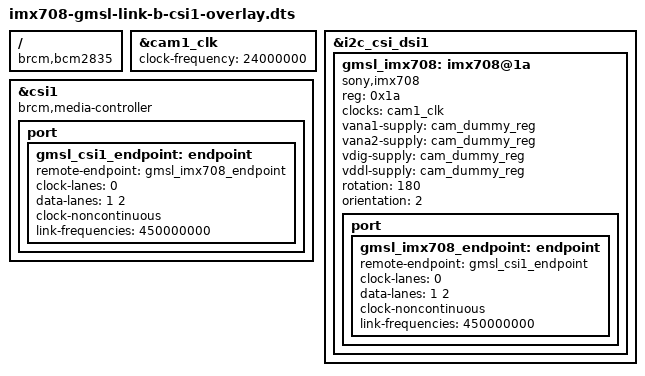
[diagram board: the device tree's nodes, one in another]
// SPDX-License-Identifier: GPL-2.0-only
/*
 * Sensor-only IMX708 overlay for the BE-IIS GMSL2 Link-B / CSI1 test.
 *
 * This overlay intentionally contains no MAX96716A or MAX96717 node.
 * Those devices, Link B, camera power, XCLR and the MIPI tunnel are
 * configured through I2C by the BE-IIS bring-up sequence.
 *
 * The sensor I2C bus is i2c_csi_dsi1 (/dev/i2c-11 on the test system).
 * The video endpoint is CSI1.
 */
/dts-v1/;
/plugin/;

/ {
	compatible = "brcm,bcm2835";

	fragment@0 {
		target = <&cam1_clk>;
		__overlay__ {
			status = "okay";
			clock-frequency = <24000000>;
		};
	};

	fragment@1 {
		target = <&i2c_csi_dsi1>;
		__overlay__ {
			#address-cells = <1>;
			#size-cells = <0>;
			status = "okay";

			gmsl_imx708: imx708@1a {
				compatible = "sony,imx708";
				reg = <0x1a>;
				status = "okay";

				/*
				 * The physical 24MHz clock is generated by MAX96717.
				 * cam1_clk only fulfils the IMX708 driver's clock handle.
				 */
				clocks = <&cam1_clk>;
				clock-names = "inclk";

				/*
				 * The MAX96717 controls sensor supply and reset. Keep
				 * Linux from operating any Raspberry Pi camera regulator.
				 */
				vana1-supply = <&cam_dummy_reg>;
				vana2-supply = <&cam_dummy_reg>;
				vdig-supply = <&cam_dummy_reg>;
				vddl-supply = <&cam_dummy_reg>;

				rotation = <180>;
				orientation = <2>;

				port {
					gmsl_imx708_endpoint: endpoint {
						remote-endpoint = <&gmsl_csi1_endpoint>;
						clock-lanes = <0>;
						data-lanes = <1 2>;
						clock-noncontinuous;
						link-frequencies =
							/bits/ 64 <450000000>;
					};
				};
			};
		};
	};

	fragment@2 {
		target = <&csi1>;
		__overlay__ {
			status = "okay";
			brcm,media-controller;

			port {
				gmsl_csi1_endpoint: endpoint {
					remote-endpoint = <&gmsl_imx708_endpoint>;
					clock-lanes = <0>;
					data-lanes = <1 2>;
					clock-noncontinuous;
					link-frequencies =
						/bits/ 64 <450000000>;
				};
			};
		};
	};
};
